# EFR32FG23B010F512IM48 register map
Vendor: Silicon Labs; Series: EFR32; File version: C
CPU: CM33 r0p4, little endian, MPU, FPU, DSP, VTOR, 4 interrupt priority bits, 8 SAU regions
Registers are 32-bit, read-write, reset 0x0 unless marked. A register's access mark holds for its fields unless they carry their own. Offsets are from the block's base; [hi:lo] are bit positions; {n}, {i} and the like mark numbered series; 'fields as' and 'values as' point back to an identical list.

## DEVINFO — DEVINFO Registers
Base 0x0FE08000
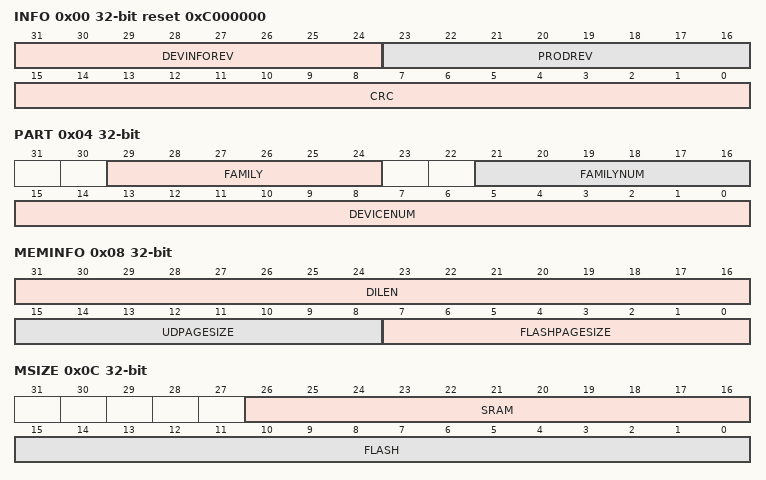
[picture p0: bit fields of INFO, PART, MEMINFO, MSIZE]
0x00 INFO ro reset 0xC000000 — Version of the device info structure being used
  [31:24] DEVINFOREV — DI Page Version
  [23:16] PRODREV — Production Revision
  [15:0] CRC
0x04 PART ro — Part description
  [29:24] FAMILY — Device Family
    0=FG (Flex Gecko); 3=ZG (Z-Wave Gecko); 5=PG (Pearl Gecko); 8=SG (Sidewalk Gecko)
  [21:16] FAMILYNUM — Device Family
  [15:0] DEVICENUM — Device Number
0x08 MEMINFO ro — Flash page size and misc. chip information
  [31:16] DILEN — Length of DI Page
  [15:8] UDPAGESIZE — User Data Page Size
  [7:0] FLASHPAGESIZE
0x0C MSIZE ro — Flash and SRAM Memory size in kB
  [26:16] SRAM — Sram Size
  [15:0] FLASH — Flash Size
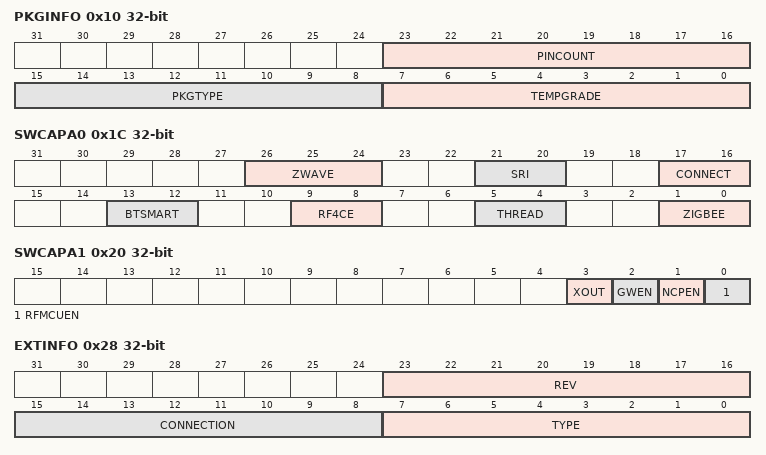
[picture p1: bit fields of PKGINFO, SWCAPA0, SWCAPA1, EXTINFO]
0x10 PKGINFO ro — Miscellaneous device information
  [23:16] PINCOUNT
  [15:8] PKGTYPE — Package Type
    74=WLCSP (WLCSP package); 76=BGA (BGA package); 77=QFN (QFN package); 81=QFP (QFP package)
  [7:0] TEMPGRADE — Temperature Grade
    0=N40TO85 (-40 to 85 degC); 1=N40TO125 (-40 to 125 degC); 2=N40TO105 (-40 to 105 degC); 3=N0TO70 (0 to 70 degC)
0x14 CUSTOMINFO ro — Custom information
  [31:16] PARTNO — Part Number
0x18 SWFIX ro reset 0xFFFFFFFF — Used to track s/w workaround info
  [31:0] RSV — Reserved
0x1C SWCAPA0 ro — Software Capability Vector 0
  [26:24] ZWAVE — Z-Wave Capability
    0=LEVEL0 (Z-Wave stack capability not available); 1=LEVEL1 (Z-Wave Gateway); 2=LEVEL2 (Z-Wave End Device); 3=LEVEL3 (Z-Wave Sensor); 4=LEVEL4 (Z-Wave Lighting)
  [21:20] SRI — RAIL Capability
    0=LEVEL0 (RAIL capability not available); 1=LEVEL1 (RAIL enabled); 2=LEVEL2 (N/A); 3=LEVEL3 (N/A)
  [17:16] CONNECT — Connect Capability
    0=LEVEL0 (Connect stack capability not available); 1=LEVEL1 (Connect enabled); 2=LEVEL2 (N/A); 3=LEVEL3 (N/A)
  [13:12] BTSMART — Bluetooth Smart Capability
    0=LEVEL0 (Bluetooth SMART stack capability not available); 1=LEVEL1 (Bluetooth SMART enabled); 2=LEVEL2 (N/A); 3=LEVEL3 (N/A)
  [9:8] RF4CE — RF4CE Capability
    0=LEVEL0 (Thread stack capability not available); 1=LEVEL1 (Thread stack enabled); 2=LEVEL2 (N/A); 3=LEVEL3 (N/A)
  [5:4] THREAD — Thread Capability
    0=LEVEL0 (RF4CE stack capability not available); 1=LEVEL1 (RF4CE stack enabled); 2=LEVEL2 (N/A); 3=LEVEL3 (N/A)
  [1:0] ZIGBEE — Zigbee Capability
    0=LEVEL0 (ZigBee stack capability not available); 1=LEVEL1 (GreenPower only); 2=LEVEL2 (ZigBee and GreenPower); 3=LEVEL3 (ZigBee Only)
0x20 SWCAPA1 ro — Software Capability Vector 1
  [3] XOUT
  [2] GWEN — Gateway
  [1] NCPEN — NCP
  [0] RFMCUEN — RF-MCU
0x28 EXTINFO ro — External component description
  [23:16] REV — Revision
  [15:8] CONNECTION
    0=SPI (SPI control interface); 255=NONE (No interface)
  [7:0] TYPE
    255=NONE
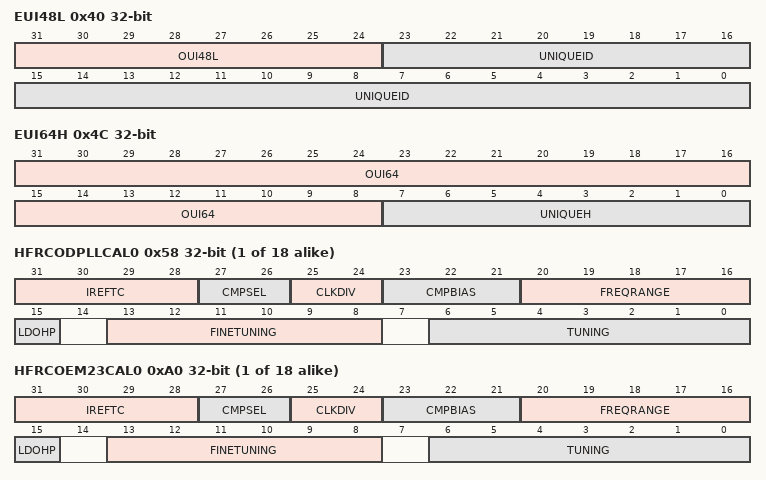
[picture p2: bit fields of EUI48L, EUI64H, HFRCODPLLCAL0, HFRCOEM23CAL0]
0x40 EUI48L ro — MA-L compliant EUI48 OUI (low bits) and Unique Identifier (24-bit)
  [31:24] OUI48L, [23:0] UNIQUEID
0x44 EUI48H ro reset 0xFFFF0000 — MA-L compliant EUI48 OUI (high bits)
  [15:0] OUI48H
0x48 EUI64L ro — MA-L compliant EUI64 Unique Identifier (low bits)
  [31:0] UNIQUEL
0x4C EUI64H ro — MA-L compliant EUI64 OUI and Unique Identifier (high bits)
  [31:8] OUI64, [7:0] UNIQUEH
0x50 CALTEMP ro — Calibration Temperature Information
  [7:0] TEMP — Cal Temp
0x54 EMUTEMP ro — EMU Temperature Sensor Calibration
  [10:2] EMUTEMPROOM — Emu Room Temperature
{0x58+4i} HFRCODPLLCAL{i} ro (i=0..17) — HFRCODPLL Calibration
  [31:28] IREFTC, [27:26] CMPSEL, [25:24] CLKDIV, [23:21] CMPBIAS, [20:16] FREQRANGE, [15] LDOHP, [13:8] FINETUNING, [6:0] TUNING
{0xA0+4i} HFRCOEM23CAL{i} ro (i=0..17) — HFRCOEM23 Calibration
  fields as HFRCODPLLCAL0
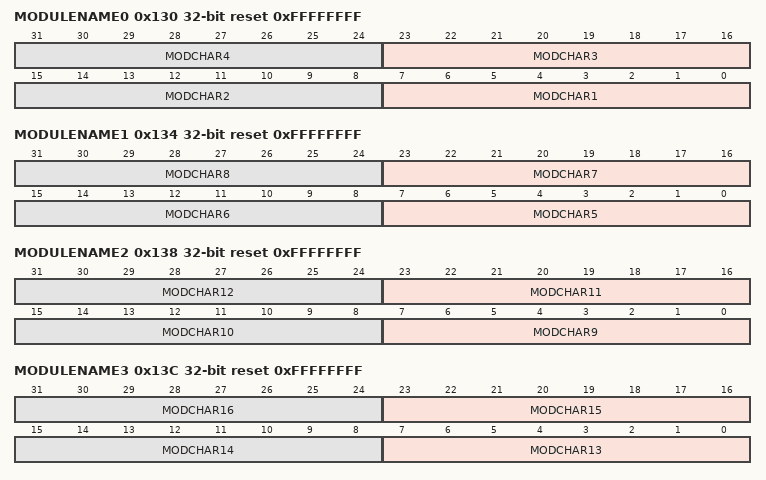
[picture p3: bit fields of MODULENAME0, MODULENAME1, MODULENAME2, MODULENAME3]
0x130 MODULENAME0 ro reset 0xFFFFFFFF — Characters 1-4 of Module Name stored as a null terminated string
  [8n-1:8n-8] MODCHAR{n} (n=1..4)
0x134 MODULENAME1 ro reset 0xFFFFFFFF — Characters 5-8 of Module Name stored as a null terminated string
  [8n-33:8n-40] MODCHAR{n} (n=5..8)
0x138 MODULENAME2 ro reset 0xFFFFFFFF — Characters 9-12 of Module Name stored as a null terminated string
  [8n-65:8n-72] MODCHAR{n} (n=9..12)
0x13C MODULENAME3 ro reset 0xFFFFFFFF — Characters 13-16 of Module Name stored as a null terminated string
  [8n-97:8n-104] MODCHAR{n} (n=13..16)
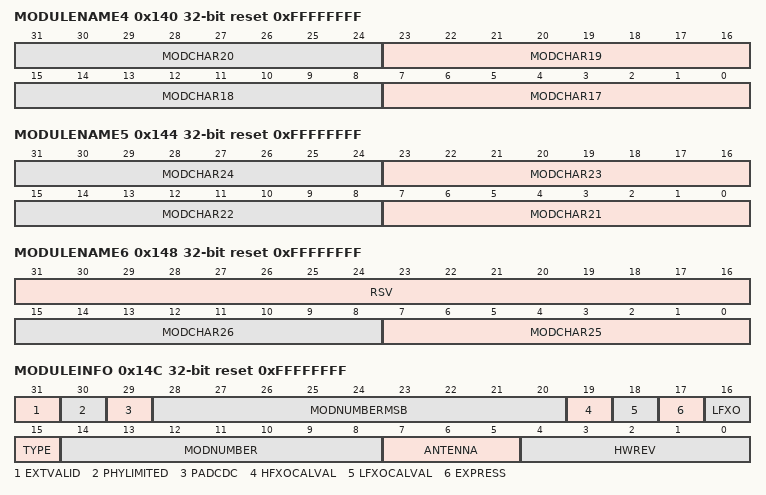
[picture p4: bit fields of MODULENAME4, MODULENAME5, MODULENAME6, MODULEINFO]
0x140 MODULENAME4 ro reset 0xFFFFFFFF — Characters 17-20 of Module Name stored as a null terminated string
  [8n-129:8n-136] MODCHAR{n} (n=17..20)
0x144 MODULENAME5 ro reset 0xFFFFFFFF — Characters 21-24 of Module Name stored as a null terminated string
  [8n-161:8n-168] MODCHAR{n} (n=21..24)
0x148 MODULENAME6 ro reset 0xFFFFFFFF — Characters 25-26 of Module Name stored as a null terminated string
  [31:16] RSV, [15:8] MODCHAR26, [7:0] MODCHAR25
0x14C MODULEINFO ro reset 0xFFFFFFFF — Module Information
  [31] EXTVALID
    0=EXTUSED; 1=EXTUNUSED
  [30] PHYLIMITED
    0=LIMITED; 1=UNLIMITED
  [29] PADCDC
    0=VDCDC; 1=OTHER
  [28:20] MODNUMBERMSB
  [19] HFXOCALVAL
    0=VALID; 1=NOTVALID
  [18] LFXOCALVAL
    0=VALID; 1=NOTVALID
  [17] EXPRESS
    0=SUPPORTED; 1=NONE
  [16] LFXO
    0=NONE; 1=PRESENT
  [15] TYPE
    0=PCB; 1=SIP
  [14:8] MODNUMBER
  [7:5] ANTENNA
    0=BUILTIN; 1=CONNECTOR; 2=RFPAD; 3=INVERTEDF
  [4:0] HWREV
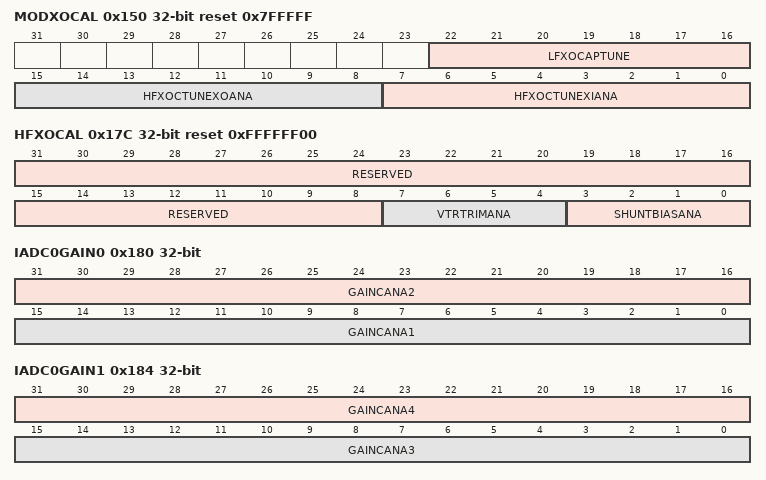
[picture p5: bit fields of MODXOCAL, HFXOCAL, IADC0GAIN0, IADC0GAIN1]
0x150 MODXOCAL ro reset 0x7FFFFF — Module Crystal Oscillator Calibration
  [22:16] LFXOCAPTUNE, [15:8] HFXOCTUNEXOANA, [7:0] HFXOCTUNEXIANA
0x17C HFXOCAL ro reset 0xFFFFFF00 — High Frequency Crystal Oscillator Calibration data
  [31:8] RESERVED — New BitField
  [7:4] VTRTRIMANA
  [3:0] SHUNTBIASANA
    0=I20UA; 1=I30UA; 2=I40UA; 3=I50UA; 4=I60UA; 5=I70UA; 6=I80UA; 7=I90UA; 8=I100UA; 9=I110UA; 10=I120UA; 11=I130UA; 12=I140UA; 13=I150UA; 14=I160UA; 15=I170UA
0x180 IADC0GAIN0 ro — IADC0 Gain Calibration Info
  [31:16] GAINCANA2, [15:0] GAINCANA1
0x184 IADC0GAIN1 ro — IADC0 Gain Calibration Info
  [31:16] GAINCANA4, [15:0] GAINCANA3
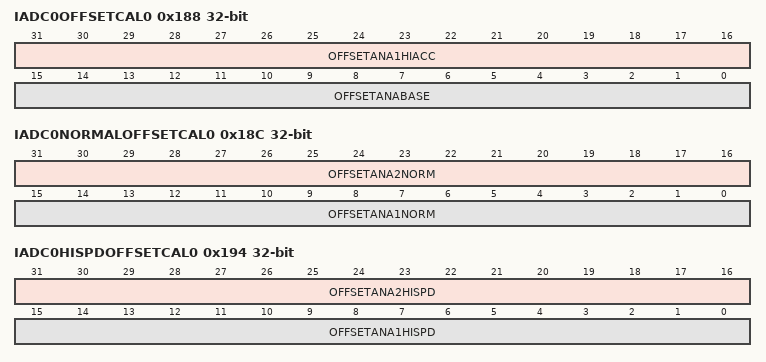
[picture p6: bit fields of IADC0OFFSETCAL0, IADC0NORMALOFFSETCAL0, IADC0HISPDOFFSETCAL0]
0x188 IADC0OFFSETCAL0 ro — IADC0 Offset Calibration Info
  [31:16] OFFSETANA1HIACC, [15:0] OFFSETANABASE
0x18C IADC0NORMALOFFSETCAL0 ro — IADC0 Normal Offset Calibration Info
  [31:16] OFFSETANA2NORM, [15:0] OFFSETANA1NORM
0x190 IADC0NORMALOFFSETCAL1 ro — IADC0 Normal Offset Calibration Info
  [15:0] OFFSETANA3NORM
0x194 IADC0HISPDOFFSETCAL0 ro — IADC High Speed Offset Calibration Info
  [31:16] OFFSETANA2HISPD, [15:0] OFFSETANA1HISPD
0x198 IADC0HISPDOFFSETCAL1 ro — IADC High Speed Offset Calibration Info
  [15:0] OFFSETANA3HISPD
0x1FC LEGACY ro reset 0x800000 — This is the legacy device detection information for tools compatability
  [23:16] DEVICEFAMILY
    16=EFR32MG1P (EFR32 Mighty Gecko Family Series 1 Device Config 1); 17=EFR32MG1B (EFR32 Mighty Gecko Family Series 1 Device Config 1); 18=EFR32MG1V (EFR32 Mighty Gecko Family Series 1 Device Config 1); 19=EFR32BG1P (EFR32 Blue Gecko Family Series 1 Device Config 1); 20=EFR32BG1B (EFR32 Blue Gecko Family Series 1 Device Config 1); 21=EFR32BG1V (EFR32 Blue Gecko Family Series 1 Device Config 1); 25=EFR32FG1P (EFR32 Flex Gecko Family Series 1 Device Config 1); 26=EFR32FG1B (EFR32 Flex Gecko Family Series 1 Device Config 1); 27=EFR32FG1V (EFR32 Flex Gecko Family Series 1 Device Config 1); 28=EFR32MG12P (EFR32 Mighty Gecko Family Series 1 Device Config 2); 29=EFR32MG12B (EFR32 Mighty Gecko Family Series 1 Device Config 2); 30=EFR32MG12V (EFR32 Mighty Gecko Family Series 1 Device Config 2); 31=EFR32BG12P (EFR32 Blue Gecko Family Series 1 Device Config 2); 32=EFR32BG12B (EFR32 Blue Gecko Family Series 1 Device Config 2); 33=EFR32BG12V (EFR32 Blue Gecko Family Series 1 Device Config 2); 37=EFR32FG12P (EFR32 Flex Gecko Family Series 1 Device Config 2); 38=EFR32FG12B (EFR32 Flex Gecko Family Series 1 Device Config 2); 39=EFR32FG12V (EFR32 Flex Gecko Family Series 1 Device Config 2); 40=EFR32MG13P (EFR32 Mighty Gecko Family Series 13 Device Config 3); 41=EFR32MG13B (EFR32 Mighty Gecko Family Series 13 Device Config 3); 42=EFR32MG13V (EFR32 Mighty Gecko Family Series 1 Device Config 3); 43=EFR32BG13P (EFR32 Blue Gecko Family Series 1 Device Config 3); 44=EFR32BG13B (EFR32 Blue Gecko Family Series 1 Device Config 3); 45=EFR32BG13V (EFR32 Blue Gecko Family Series 1 Device Config 3); 49=EFR32FG13P (EFR32 Flex Gecko Family Series 1 Device Config 3); 50=EFR32FG13B (EFR32 Flex Gecko Family Series 1 Device Config 3); 51=EFR32FG13V (EFR32 Flex Gecko Family Series 1 Device Config 3); 52=EFR32MG14P (EFR32 Mighty Gecko Family Series 1 Device Config 4); 53=EFR32MG14B (EFR32 Mighty Gecko Family Series 1 Device Config 4); 54=EFR32MG14V (EFR32 Mighty Gecko Family Series 1 Device Config 4); 55=EFR32BG14P (EFR32 Blue Gecko Family Series 1 Device Config 4); 56=EFR32BG14B (EFR32 Blue Gecko Family Series 1 Device Config 4); 57=EFR32BG14V (EFR32 Blue Gecko Family Series 1 Device Config 4); 61=EFR32FG14P (EFR32 Flex Gecko Family Series 1 Device Config 4); 62=EFR32FG14B (EFR32 Flex Gecko Family Series 1 Device Config 4); 63=EFR32FG14V (EFR32 Flex Gecko Family Series 1 Device Config 4); 71=EFM32G (EFM32 Gecko Device Family); 72=EFM32GG (EFM32 Giant Gecko Device Family); 73=EFM32TG (EFM32 Tiny Gecko Device Family); 74=EFM32LG (EFM32 Leopard Gecko Device Family); 75=EFM32WG (EFM32 Wonder Gecko Device Family); 76=EFM32ZG (EFM32 Zero Gecko Device Family); 77=EFM32HG (EFM32 Happy Gecko Device Family); 81=EFM32PG1B (EFM32 Pearl Gecko Device Family Series 1 Device Config 1); 83=EFM32JG1B (EFM32 Jade Gecko Device Family Series 1 Device Config 1); 85=EFM32PG12B (EFM32 Pearl Gecko Device Family Series 1 Device Config 2); 87=EFM32JG12B (EFM32 Jade Gecko Device Family Series 1 Device Config 2); 89=EFM32PG13B (EFM32 Pearl Gecko Device Family Series 1 Device Config 3); 91=EFM32JG13B (EFM32 Jade Gecko Device Family Series 1 Device Config 3); 100=EFM32GG11B (EFM32 Giant Gecko Device Family Series 1 Device Config 1); 103=EFM32TG11B (EFM32 Giant Gecko Device Family Series 1 Device Config 1); 120=EZR32LG (EZR32 Leopard Gecko Device Family); 121=EZR32WG (EZR32 Wonder Gecko Device Family); 122=EZR32HG (EZR32 Happy Gecko Device Family); 128=SERIES2V0 (DI page is encoded with the series 2 layout. Check alternate location.)
0x25C RTHERM ro
  [15:0] RTHERM
